AUTOSAR XML (schema 314)
package /ComponentType
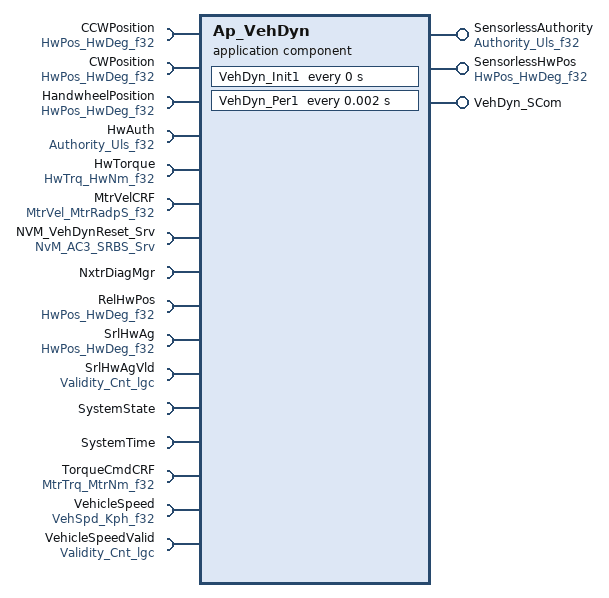
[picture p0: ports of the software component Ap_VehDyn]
  application software component type Ap_VehDyn
    provide port SensorlessAuthority: unqueued-sender-com-spec{data-element=Uls_f32, can-invalidate=false, init-value=D_ZERO_ULS_F32}, provided-interface=Authority_Uls_f32
    provide port SensorlessHwPos: unqueued-sender-com-spec{data-element=HwDeg_f32, can-invalidate=false, init-value=D_ZERO_ULS_F32}, provided-interface=HwPos_HwDeg_f32
    provide port VehDyn_SCom: provided-com-specs=[{operation=ForceCenter, queue-length=1}, {operation=ResetCenter, queue-length=1}], provided-interface=VehDyn_SCom
    16 x require port:
      CCWPosition: unqueued-receiver-com-spec{data-element=HwDeg_f32, init-value=D_ZERO_ULS_F32}, required-interface=HwPos_HwDeg_f32
      CWPosition: unqueued-receiver-com-spec{data-element=HwDeg_f32, init-value=D_ZERO_ULS_F32}, required-interface=HwPos_HwDeg_f32
      HandwheelPosition: unqueued-receiver-com-spec{data-element=HwDeg_f32, init-value=D_ZERO_ULS_F32}, required-interface=HwPos_HwDeg_f32
      HwAuth: unqueued-receiver-com-spec{data-element=Uls_f32, init-value=D_ZERO_ULS_F32}, required-interface=Authority_Uls_f32
      HwTorque: unqueued-receiver-com-spec{data-element=HwNm_f32, init-value=D_ZERO_ULS_F32}, required-interface=HwTrq_HwNm_f32
      MtrVelCRF: unqueued-receiver-com-spec{data-element=MtrRadpS_f32, init-value=D_ZERO_ULS_F32}, required-interface=MtrVel_MtrRadpS_f32
      NVM_VehDynReset_Srv: required-com-specs=[EraseBlock, GetErrorStatus, InvalidateNvBlock, ReadBlock, SetRamBlockStatus, WriteBlock], required-interface=NvM_AC3_SRBS_Srv
      NxtrDiagMgr: required-com-specs=[GetNTCActive, GetNTCFailed, GetNTCStatus, SetNTCStatus], required-interface=NxtrDiagMgr
      RelHwPos: unqueued-receiver-com-spec{data-element=HwDeg_f32, init-value=D_ZERO_ULS_F32}, required-interface=HwPos_HwDeg_f32
      SrlHwAg: unqueued-receiver-com-spec{data-element=HwDeg_f32, init-value=D_ZERO_ULS_F32}, required-interface=HwPos_HwDeg_f32
      SrlHwAgVld: unqueued-receiver-com-spec{data-element=Cnt_lgc, init-value=D_FALSE_CNT_LGC}, required-interface=Validity_Cnt_lgc
      SystemState: required-interface=SystemState
      SystemTime: required-interface=SystemTime
        required-com-specs:
          DtrmnElapsedTime_mS_u16
          DtrmnElapsedTime_mS_u32
          DtrmnElapsedTime_uS_u16
          DtrmnElapsedTime_uS_u32
          GetSystemTime_mS_u32
          GetSystemTime_uS_u32
      TorqueCmdCRF: unqueued-receiver-com-spec{data-element=MtrNm_f32, init-value=D_ZERO_ULS_F32}, required-interface=MtrTrq_MtrNm_f32
      VehicleSpeed: unqueued-receiver-com-spec{data-element=Kph_f32, init-value=D_ZERO_ULS_F32}, required-interface=VehSpd_Kph_f32
      VehicleSpeedValid: unqueued-receiver-com-spec{data-element=Cnt_lgc, init-value=D_FALSE_CNT_LGC}, required-interface=Validity_Cnt_lgc
  internal behavior Ap_VehDyn_InternalBehavior: component=Ap_VehDyn
    timing event VehDyn_Init1_InitEvent: start-on-event=VehDyn_Init1, period=0
    timing event TMT_VehDyn_Per1: start-on-event=VehDyn_Per1, period=0.002
    operation invoked event OIT_VehDyn_SCom_ForceCenter_VehDyn_SCom_ForceCenter: start-on-event=VehDyn_SCom_ForceCenter, operation=VehDyn_SCom.ForceCenter
    operation invoked event OIT_VehDyn_SCom_ResetCenter_VehDyn_SCom_ResetCenter: start-on-event=VehDyn_SCom_ResetCenter, operation=VehDyn_SCom.ResetCenter
    mode switch event MST_VehDyn_Trns1_0: start-on-event=VehDyn_Trns1, activation=ENTRY, mode=SystemState.Mode.OFF
    per instance memory MotPosReset: type=VehDyn_DataType, type-definition=/DataType/VehDyn_DataType
    port-api-options:
      enable-take-address=false, indirect-api=false, port=CCWPosition
      enable-take-address=false, indirect-api=false, port=CWPosition
      enable-take-address=false, indirect-api=false, port=HandwheelPosition
      enable-take-address=false, indirect-api=false, port=HwAuth
      enable-take-address=false, indirect-api=false, port=HwTorque
      enable-take-address=false, indirect-api=false, port=MtrVelCRF
      enable-take-address=false, indirect-api=false, port=NVM_VehDynReset_Srv
      enable-take-address=false, indirect-api=false, port=NxtrDiagMgr
      enable-take-address=false, indirect-api=false, port=RelHwPos
      enable-take-address=false, indirect-api=false, port=SensorlessAuthority
      enable-take-address=false, indirect-api=false, port=SensorlessHwPos
      enable-take-address=false, indirect-api=false, port=SrlHwAg
      enable-take-address=false, indirect-api=false, port=SrlHwAgVld
      enable-take-address=false, indirect-api=false, port=SystemState
      enable-take-address=false, indirect-api=false, port=SystemTime
      enable-take-address=false, indirect-api=false, port=TorqueCmdCRF
      enable-take-address=false, indirect-api=false, port=VehDyn_SCom
      enable-take-address=false, indirect-api=false, port=VehicleSpeed
      enable-take-address=false, indirect-api=false, port=VehicleSpeedValid
    5 x runnable:
      VehDyn_Init1
        4 x sync call, all with timeout=0:
          SC_NVM_VehDynReset_Srv_GetErrorStatus: operation=NVM_VehDynReset_Srv.GetErrorStatus
          SC_NxtrDiagMgr_GetNTCActive: operation=NxtrDiagMgr.GetNTCActive
          SC_NxtrDiagMgr_SetNTCStatus: operation=NxtrDiagMgr.SetNTCStatus
          SC_SystemTime_GetSystemTime_mS_u32: operation=SystemTime.GetSystemTime_mS_u32
      VehDyn_Per1
        10 x data read access:
          READ_CCWPosition_HwDeg_f32: data-element=CCWPosition.HwDeg_f32
          READ_CWPosition_HwDeg_f32: data-element=CWPosition.HwDeg_f32
          READ_HwTorque_HwNm_f32: data-element=HwTorque.HwNm_f32
          READ_MtrVelCRF_MtrRadpS_f32: data-element=MtrVelCRF.MtrRadpS_f32
          READ_RelHwPos_HwDeg_f32: data-element=RelHwPos.HwDeg_f32
          READ_SrlHwAg_HwDeg_f32: data-element=SrlHwAg.HwDeg_f32
          READ_SrlHwAgVld_Cnt_lgc: data-element=SrlHwAgVld.Cnt_lgc
          READ_TorqueCmdCRF_MtrNm_f32: data-element=TorqueCmdCRF.MtrNm_f32
          READ_VehicleSpeed_Kph_f32: data-element=VehicleSpeed.Kph_f32
          READ_VehicleSpeedValid_Cnt_lgc: data-element=VehicleSpeedValid.Cnt_lgc
        data write access WRITE_SensorlessAuthority_Uls_f32: data-element=SensorlessAuthority.Uls_f32
        data write access WRITE_SensorlessHwPos_HwDeg_f32: data-element=SensorlessHwPos.HwDeg_f32
        sync call SC_NxtrDiagMgr_SetNTCStatus: operation=NxtrDiagMgr.SetNTCStatus, timeout=0
        sync call SC_SystemTime_DtrmnElapsedTime_mS_u32: operation=SystemTime.DtrmnElapsedTime_mS_u32, timeout=0
        sync call SC_SystemTime_GetSystemTime_mS_u32: operation=SystemTime.GetSystemTime_mS_u32, timeout=0
      VehDyn_SCom_ForceCenter
      VehDyn_SCom_ResetCenter
        sync call SC_NVM_VehDynReset_Srv_WriteBlock: operation=NVM_VehDynReset_Srv.WriteBlock, timeout=0
      VehDyn_Trns1
        data read access READ_HandwheelPosition_HwDeg_f32: data-element=HandwheelPosition.HwDeg_f32
        data read access READ_HwAuth_Uls_f32: data-element=HwAuth.Uls_f32
        sync call SC_NVM_VehDynReset_Srv_WriteBlock: operation=NVM_VehDynReset_Srv.WriteBlock, timeout=0
    service-needss:
      swc nv block needs VehDynReset: n-data-sets=0, readonly=false, reliability=LOW, resistant-to-changed-sw=false, restore-at-start=false, write-only-once=false, writing-frequency=0, writing-priority=LOW, mirror-block=MotPosReset
  swc implementation Ap_VehDyn_Implementation: behavior=Ap_VehDyn_InternalBehavior
    code-descriptors:
      code Code: type=SRC
